# STM32F401 register map
File version: 1.8
CPU: CM4 r0p1, little endian, MPU, FPU, 4 interrupt priority bits
Registers are 32-bit, read-write, reset 0x0 unless marked. A register's access mark holds for its fields unless they carry their own. Offsets are from the block's base; [hi:lo] are bit positions; {n}, {i} and the like mark numbered series; 'fields as' and 'values as' point back to an identical list.

## SYSCFG — System configuration controller
Base 0x40013800
0x00 MEMRMP — memory remap register
  [1:0] MEM_MODE
    0=Main Flash memory mapped at 0x0000 0000; 1=System Flash memory mapped at 0x0000 0000; 3=Embedded SRAM mapped at 0x0000 0000
0x04 PMC — peripheral mode configuration register
  [16] ADC1DC2
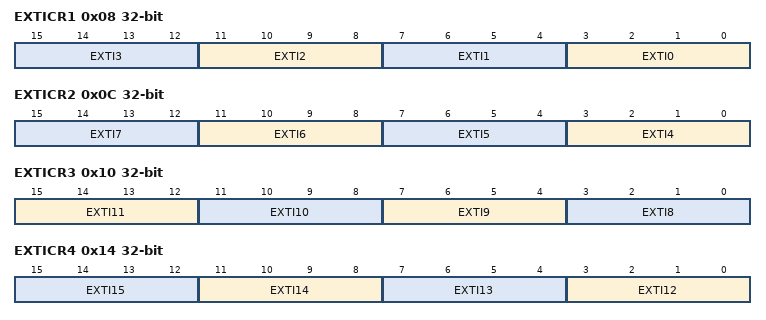
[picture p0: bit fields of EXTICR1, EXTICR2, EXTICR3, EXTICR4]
0x08 EXTICR1 — external interrupt configuration register 1
  [all] fields
    0=PA (Select PAx as the source input for the EXTIx external interrupt); 1=PB (Select PBx as the source input for the EXTIx external interrupt); 2=PC (Select PCx as the source input for the EXTIx external interrupt); 3=PD (Select PDx as the source input for the EXTIx external interrupt); 4=PE (Select PEx as the source input for the EXTIx external interrupt); 7=PH (Select PHx as the source input for the EXTIx external interrupt)
  [4n+3:4n] EXTI{n} (n=0..3) — EXTI x configuration (x = 0 to 3)
0x0C EXTICR2 — external interrupt configuration register 2
  [all] fields
    values as the fields of EXTICR1
  [4n-13:4n-16] EXTI{n} (n=4..7) — EXTI x configuration (x = 4 to 7)
0x10 EXTICR3 — external interrupt configuration register 3
  [all] fields
    values as the fields of EXTICR1
  [15:12] EXTI11 — EXTI x configuration (x = 8 to 11)
  [11:8] EXTI10
  [7:4] EXTI9 — EXTI x configuration (x = 8 to 11)
  [3:0] EXTI8 — EXTI x configuration (x = 8 to 11)
0x14 EXTICR4 — external interrupt configuration register 4
  [all] fields
    values as the fields of EXTICR1
  [4n-45:4n-48] EXTI{n} (n=12..15) — EXTI x configuration (x = 12 to 15)
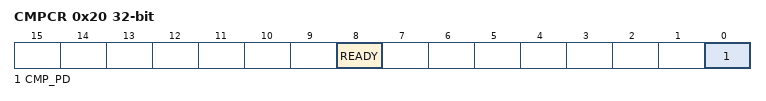
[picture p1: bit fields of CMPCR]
0x20 CMPCR ro — Compensation cell control register
  [8] READY
    0=NotReady (I/O compensation cell not ready); 1=Ready (I/O compensation cell ready)
  [0] CMP_PD rw — Compensation cell power-down
    0=PowerDown (I/O compensation cell power-down mode); 1=Enabled (I/O compensation cell enabled)

## WWDG — Window watchdog
Base 0x40002C00
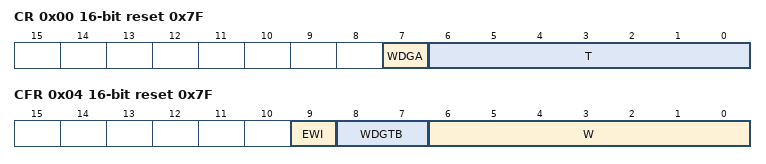
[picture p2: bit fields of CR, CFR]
0x00 CR 16-bit reset 0x7F — Control register
  [7] WDGA — Activation bit
    0=Disabled (Watchdog disabled); 1=Enabled (Watchdog enabled)
  [6:0] T — 7-bit counter (MSB to LSB)
0x04 CFR 16-bit reset 0x7F — Configuration register
  [9] EWI — Early wakeup interrupt
    on write: 1=Enable (interrupt occurs whenever the counter reaches the value 0x40)
  [8:7] WDGTB — Timer base
    0=Div1 (Counter clock (PCLK1 div 4096) div 1); 1=Div2 (Counter clock (PCLK1 div 4096) div 2); 2=Div4 (Counter clock (PCLK1 div 4096) div 4); 3=Div8 (Counter clock (PCLK1 div 4096) div 8)
  [6:0] W — 7-bit window value
0x08 SR 16-bit — Status register
  [0] EWIF write-0-clears — Early wakeup interrupt flag
    on read: 0=Finished (The EWI Interrupt Service Routine has been serviced); 1=Pending (The EWI Interrupt Service Routine has been triggered) | on write: 0=Finished (The EWI Interrupt Service Routine has been serviced)

## GPIOH — General-purpose I/Os
Base 0x40021C00
Same registers: GPIOC 0x40020800, GPIOD 0x40020C00, GPIOE 0x40021000
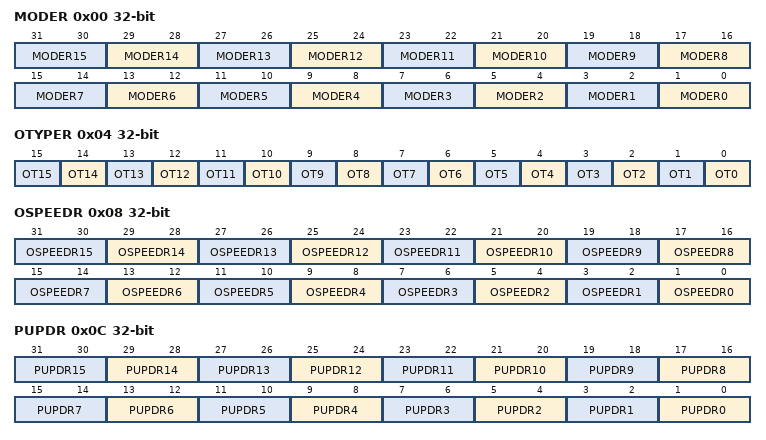
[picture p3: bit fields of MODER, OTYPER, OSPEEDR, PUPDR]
0x00 MODER — GPIO port mode register
  [2n+1:2n] MODER{n} (n=0..15) — Port x configuration pin {n}
    0=Input mode (reset state); 1=Output (General purpose output mode); 2=Alternate function mode; 3=Analog mode
0x04 OTYPER — GPIO port output type register
  [n] OT{n} (n=0..15) — Port x configuration pin {n}
    0=PushPull (Output push-pull (reset state)); 1=OpenDrain (Output open-drain)
0x08 OSPEEDR — GPIO port output speed register
  [2n+1:2n] OSPEEDR{n} (n=0..15) — Port x configuration pin {n}
    0=LowSpeed; 1=MediumSpeed; 2=HighSpeed; 3=VeryHighSpeed
0x0C PUPDR — GPIO port pull-up/pull-down register
  [2n+1:2n] PUPDR{n} (n=0..15) — Port x configuration pin {n}
    0=Floating (No pull-up, pull-down); 1=PullUp; 2=PullDown
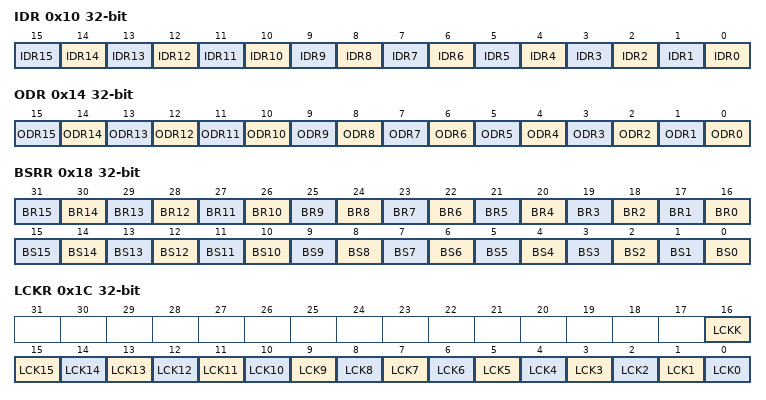
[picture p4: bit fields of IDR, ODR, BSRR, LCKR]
0x10 IDR ro — GPIO port input data register
  [n] IDR{n} (n=0..15) — Port input data pin {n}
    0=Low (Input is logic low); 1=High (Input is logic high)
0x14 ODR — GPIO port output data register
  [n] ODR{n} (n=0..15) — Port output data pin {n}
    0=Low (Set output to logic low); 1=High (Set output to logic high)
0x18 BSRR wo — GPIO port bit set/reset register
  [n+16] BR{n} (n=0..15) — Port x reset pin {n}
    1=Resets the corresponding ODRx bit
  [n] BS{n} (n=0..15) — Port x set pin {n}
    1=Set (Sets the corresponding ODRx bit)
0x1C LCKR — GPIO port configuration lock register
  [16] LCKK — Port x lock bit y (y= 0..15)
    0=NotActive (Port configuration lock key not active); 1=Active (Port configuration lock key active)
  [n] LCK{n} (n=0..15) — Port x lock pin {n}
    0=Unlocked (Port configuration not locked); 1=Locked (Port configuration locked)
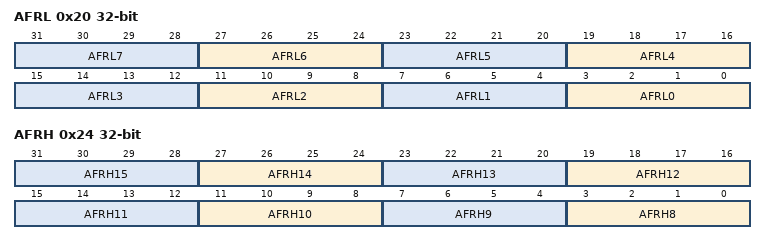
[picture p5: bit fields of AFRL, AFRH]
0x20 AFRL — GPIO alternate function low register
  [3:0] AFR{x} (x=L0,L1,L2,L3,L4,L5,L6,L7; step 4) — Alternate function selection for port x bit y (y = 0..7)
    {v}=AF{v} (v=0..15)
0x24 AFRH — GPIO alternate function high register
  [3:0] AFR{x} (x=H8,H9,H10,H11,H12,H13,H14,H15; step 4) — Alternate function selection for port x bit y (y = 8..15)
    {v}=AF{v} (v=0..15)

## GPIOB — General-purpose I/Os
Base 0x40020400
Registers as GPIOH; these are added or differ:
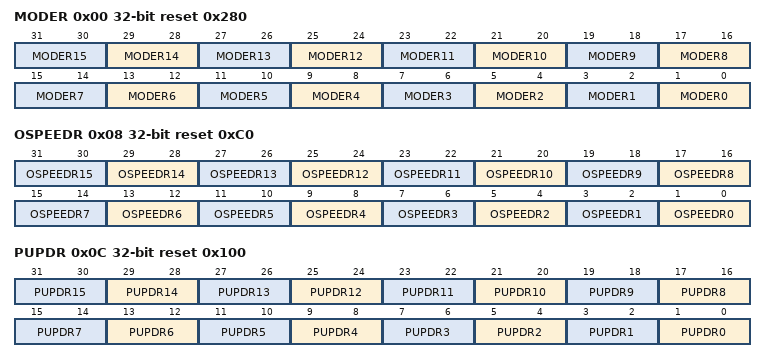
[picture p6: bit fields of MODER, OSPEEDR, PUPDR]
0x00 MODER reset 0x280 — GPIO port mode register
  [2n+1:2n] MODER{n} (n=0..15) — Port x configuration pin {n}
    0=Input mode (reset state); 1=Output (General purpose output mode); 2=Alternate function mode; 3=Analog mode
0x08 OSPEEDR reset 0xC0 — GPIO port output speed register
  [2n+1:2n] OSPEEDR{n} (n=0..15) — Port x configuration pin {n}
    0=LowSpeed; 1=MediumSpeed; 2=HighSpeed; 3=VeryHighSpeed
0x0C PUPDR reset 0x100 — GPIO port pull-up/pull-down register
  [2n+1:2n] PUPDR{n} (n=0..15) — Port x configuration pin {n}
    0=Floating (No pull-up, pull-down); 1=PullUp; 2=PullDown

## GPIOA — General-purpose I/Os
Base 0x40020000
Registers as GPIOH; these are added or differ:
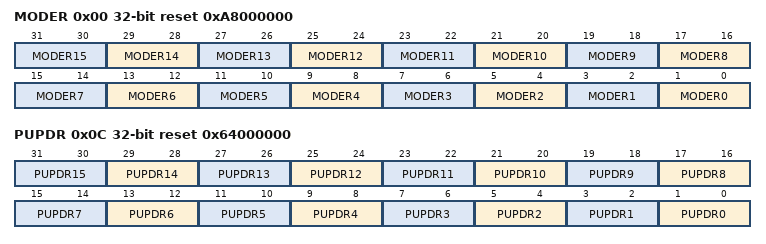
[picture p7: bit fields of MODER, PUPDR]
0x00 MODER reset 0xA8000000 — GPIO port mode register
  [2n+1:2n] MODER{n} (n=0..15) — Port x configuration pin {n}
    0=Input mode (reset state); 1=Output (General purpose output mode); 2=Alternate function mode; 3=Analog mode
0x0C PUPDR reset 0x64000000 — GPIO port pull-up/pull-down register
  [2n+1:2n] PUPDR{n} (n=0..15) — Port x configuration pin {n}
    0=Floating (No pull-up, pull-down); 1=PullUp; 2=PullDown
